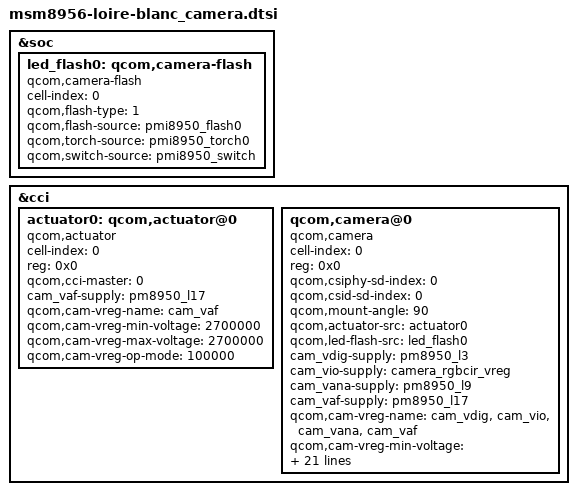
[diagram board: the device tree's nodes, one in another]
/*
 * Copyright (c) 2015-2016, The Linux Foundation. All rights reserved.
 *
 * This program is free software; you can redistribute it and/or modify
 * it under the terms of the GNU General Public License version 2 and
 * only version 2 as published by the Free Software Foundation.
 *
 * This program is distributed in the hope that it will be useful,
 * but WITHOUT ANY WARRANTY; without even the implied warranty of
 * MERCHANTABILITY or FITNESS FOR A PARTICULAR PURPOSE.  See the
 * GNU General Public License for more details.
 */

&soc {
	led_flash0: qcom,camera-flash {
		cell-index = <0>;
		compatible = "qcom,camera-flash";
		qcom,flash-type = <1>;
		qcom,flash-source = <&pmi8950_flash0>;
		qcom,torch-source = <&pmi8950_torch0>;
		qcom,switch-source = <&pmi8950_switch>;
	};
};

&cci {
	/* Remove MTP inherited nodes */
	/delete-node/ qcom,actuator@0;
	/delete-node/ qcom,actuator@1;
	/delete-node/ qcom,eeprom@0;
	/delete-node/ qcom,eeprom@1;
	/delete-node/ qcom,camera@0;
	/delete-node/ qcom,camera@1;
	/delete-node/ qcom,camera@2;
	/delete-node/ qcom,camera@78;

	actuator0: qcom,actuator@0 {
		cell-index = <0>;
		reg = <0x0>;
		compatible = "qcom,actuator";
		qcom,cci-master = <0>;
		cam_vaf-supply = <&pm8950_l17>;
		qcom,cam-vreg-name = "cam_vaf";
		qcom,cam-vreg-min-voltage = <2700000>;
		qcom,cam-vreg-max-voltage = <2700000>;
		qcom,cam-vreg-op-mode = <100000>;
	};

	qcom,camera@0 {
		cell-index = <0>;
		compatible = "qcom,camera";
		reg = <0x0>;
		qcom,csiphy-sd-index = <0>;
		qcom,csid-sd-index = <0>;
		qcom,mount-angle = <90>;
		qcom,actuator-src = <&actuator0>;
		qcom,led-flash-src = <&led_flash0>;
		cam_vdig-supply = <&pm8950_l3>;
		cam_vio-supply = <&camera_rgbcir_vreg>;
		cam_vana-supply = <&pm8950_l9>;
		cam_vaf-supply = <&pm8950_l17>;
		qcom,cam-vreg-name = "cam_vdig", "cam_vio", "cam_vana", "cam_vaf";
		qcom,cam-vreg-min-voltage = <1000000 0 2700000 2700000>;
		qcom,cam-vreg-max-voltage = <1000000 0 2700000 2700000>;
		qcom,cam-vreg-op-mode = <333000 0 46000 100000>;
		qcom,gpio-no-mux = <0>;
		pinctrl-names = "cam_default", "cam_suspend";
		pinctrl-0 = <&cam_sensor_mclk0_default &msm_gpio_35_def>;
		pinctrl-1 = <&cam_sensor_mclk0_sleep &msm_gpio_35_def>;
		gpios = <&msm_gpio 26 0>, <&msm_gpio 35 0>;
		qcom,gpio-reset = <1>;
		qcom,gpio-req-tbl-num = <0 1>;
		qcom,gpio-req-tbl-flags = <1 0>;
		qcom,gpio-req-tbl-label = "CAMIF_MCLK0", "CAM_RESET0";
		qcom,sensor-position = <0>;
		qcom,sensor-mode = <0>;
		qcom,cci-master = <0>;
		status = "ok";
		clocks = <&clock_gcc MCLK0_CLK_SRC>,
			 <&clock_gcc GCC_CAMSS_MCLK0_CLK>;
		clock-names = "cam_src_clk", "cam_clk";
		qcom,clock-rates = <24000000 0>;
	};
};
